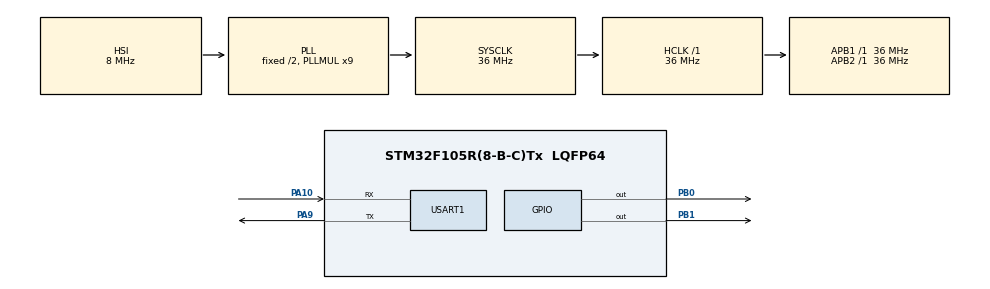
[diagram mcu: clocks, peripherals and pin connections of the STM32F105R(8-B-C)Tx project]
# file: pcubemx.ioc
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FREERTOS.Tasks01=defaultTask,0,128,StartDefaultTask,Default,NULL
Mcu.Family=STM32F1
Mcu.Name=STM32F105R(8-B-C)Tx
Mcu.Package=LQFP64
NVIC.PriorityGroup=NVIC_PRIORITYGROUP_4
NVIC.TIM1_UP_IRQn=true\:0\:0\:false\:false\:true\:false
NVIC.TimeBase=TIM1_UP_IRQn
NVIC.TimeBaseIP=TIM1
NVIC.USART1_IRQn=true\:5\:0\:false\:false\:true\:true
PA10.Mode=Asynchronous
PA10.Signal=USART1_RX
PA13.Mode=Trace_Asynchronous_SW
PA13.Signal=SYS_JTMS-SWDIO
PA14.Mode=Trace_Asynchronous_SW
PA14.Signal=SYS_JTCK-SWCLK
PA9.Mode=Asynchronous
PA9.Signal=USART1_TX
PB0.Signal=GPIO_Output
PB1.Signal=GPIO_Output
PB3.Mode=Trace_Asynchronous_SW
PB3.Signal=SYS_TRACESWO
ProjectManager.HeapSize=0x200
ProjectManager.StackSize=0x400
ProjectManager.TargetToolchain=MDK-ARM V4
RCC.AHBFreq_Value=36000000
RCC.APB1Freq_Value=36000000
RCC.APB1TimFreq_Value=36000000
RCC.APB2Freq_Value=36000000
RCC.APB2TimFreq_Value=36000000
RCC.HCLKFreq_Value=36000000
RCC.PLLMUL=RCC_PLL_MUL9
RCC.SYSCLKFreq_VALUE=36000000
RCC.SYSCLKSource=RCC_SYSCLKSOURCE_PLLCLK
RCC.USBFreq_Value=24000000
USART1.VirtualMode=VM_ASYNC
VP_FREERTOS_VS_ENABLE.Mode=Enabled
VP_SYS_VS_tim1.Mode=TIM1
board=pcubemx

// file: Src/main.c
/**
  ******************************************************************************
  * File Name          : main.c
  * Description        : Main program body
  ******************************************************************************
  * This notice applies to any and all portions of this file
  * that are not between comment pairs USER CODE BEGIN and
  * USER CODE END. Other portions of this file, whether
  * inserted by the user or by software development tools
  * are owned by their respective copyright owners.
  *
  * Copyright (c) 2017 STMicroelectronics International N.V.
  * All rights reserved.
  *
  * Redistribution and use in source and binary forms, with or without
  * modification, are permitted, provided that the following conditions are met:
  *
  * 1. Redistribution of source code must retain the above copyright notice,
  *    this list of conditions and the following disclaimer.
  * 2. Redistributions in binary form must reproduce the above copyright notice,
  *    this list of conditions and the following disclaimer in the documentation
  *    and/or other materials provided with the distribution.
  * 3. Neither the name of STMicroelectronics nor the names of other
  *    contributors to this software may be used to endorse or promote products
  *    derived from this software without specific written permission.
  * 4. This software, including modifications and/or derivative works of this
  *    software, must execute solely and exclusively on microcontroller or
  *    microprocessor devices manufactured by or for STMicroelectronics.
  * 5. Redistribution and use of this software other than as permitted under
  *    this license is void and will automatically terminate your rights under
  *    this license.
  *
  * THIS SOFTWARE IS PROVIDED BY STMICROELECTRONICS AND CONTRIBUTORS "AS IS"
  * AND ANY EXPRESS, IMPLIED OR STATUTORY WARRANTIES, INCLUDING, BUT NOT
  * LIMITED TO, THE IMPLIED WARRANTIES OF MERCHANTABILITY, FITNESS FOR A
  * PARTICULAR PURPOSE AND NON-INFRINGEMENT OF THIRD PARTY INTELLECTUAL PROPERTY
  * RIGHTS ARE DISCLAIMED TO THE FULLEST EXTENT PERMITTED BY LAW. IN NO EVENT
  * SHALL STMICROELECTRONICS OR CONTRIBUTORS BE LIABLE FOR ANY DIRECT, INDIRECT,
  * INCIDENTAL, SPECIAL, EXEMPLARY, OR CONSEQUENTIAL DAMAGES (INCLUDING, BUT NOT
  * LIMITED TO, PROCUREMENT OF SUBSTITUTE GOODS OR SERVICES; LOSS OF USE, DATA,
  * OR PROFITS; OR BUSINESS INTERRUPTION) HOWEVER CAUSED AND ON ANY THEORY OF
  * LIABILITY, WHETHER IN CONTRACT, STRICT LIABILITY, OR TORT (INCLUDING
  * NEGLIGENCE OR OTHERWISE) ARISING IN ANY WAY OUT OF THE USE OF THIS SOFTWARE,
  * EVEN IF ADVISED OF THE POSSIBILITY OF SUCH DAMAGE.
  *
  ******************************************************************************
  */
#include "main.h"
#include "stm32f1xx_hal.h"
#include "cmsis_os.h"

UART_HandleTypeDef huart1;

osThreadId defaultTaskHandle;

/* USER CODE BEGIN PV */
/* Private variables ---------------------------------------------------------*/

/* USER CODE END PV */

void SystemClock_Config(void);
static void MX_GPIO_Init(void);
static void MX_USART1_UART_Init(void);
void StartDefaultTask(void const * argument);

/* USER CODE BEGIN PFP */
/* Private function prototypes -----------------------------------------------*/
void StartDefaultTaskLed(void const * argument);

/* USER CODE END PFP */

int main(void)
{

  /* MCU Configuration----------------------------------------------------------*/

  /* Reset of all peripherals, Initializes the Flash interface and the Systick. */
  HAL_Init();

  /* Configure the system clock */
  SystemClock_Config();

  /* Initialize all configured peripherals */
  MX_GPIO_Init();
  MX_USART1_UART_Init();

  /* Create the thread(s) */
  /* definition and creation of defaultTask */
  osThreadDef(defaultTask, StartDefaultTask, osPriorityNormal, 0, 128);
  defaultTaskHandle = osThreadCreate(osThread(defaultTask), NULL);

  /* USER CODE BEGIN RTOS_THREADS */
  /* add threads, ... */
  osThreadDef(defaultTaskLed, StartDefaultTaskLed, osPriorityNormal, 0, 128);
  osThreadCreate(osThread(defaultTaskLed), NULL);
  /* USER CODE END RTOS_THREADS */

  /* Start scheduler */
  osKernelStart();

  /* We should never get here as control is now taken by the scheduler */

  /* Infinite loop */
  while (1)
  {

  }

}

/** System Clock Configuration
*/
void SystemClock_Config(void)
{

  RCC_OscInitTypeDef RCC_OscInitStruct;
  RCC_ClkInitTypeDef RCC_ClkInitStruct;

    /**Initializes the CPU, AHB and APB busses clocks
    */
  RCC_OscInitStruct.OscillatorType = RCC_OSCILLATORTYPE_HSI;
  RCC_OscInitStruct.HSIState = RCC_HSI_ON;
  RCC_OscInitStruct.HSICalibrationValue = 16;
  RCC_OscInitStruct.Prediv1Source = RCC_PREDIV1_SOURCE_HSE;
  RCC_OscInitStruct.PLL.PLLState = RCC_PLL_ON;
  RCC_OscInitStruct.PLL.PLLSource = RCC_PLLSOURCE_HSI_DIV2;
  RCC_OscInitStruct.PLL.PLLMUL = RCC_PLL_MUL9;
  RCC_OscInitStruct.PLL2.PLL2State = RCC_PLL_NONE;
  if (HAL_RCC_OscConfig(&RCC_OscInitStruct) != HAL_OK)
  {
    _Error_Handler(__FILE__, __LINE__);
  }

    /**Initializes the CPU, AHB and APB busses clocks
    */
  RCC_ClkInitStruct.ClockType = RCC_CLOCKTYPE_HCLK|RCC_CLOCKTYPE_SYSCLK
                              |RCC_CLOCKTYPE_PCLK1|RCC_CLOCKTYPE_PCLK2;
  RCC_ClkInitStruct.SYSCLKSource = RCC_SYSCLKSOURCE_PLLCLK;
  RCC_ClkInitStruct.AHBCLKDivider = RCC_SYSCLK_DIV1;
  RCC_ClkInitStruct.APB1CLKDivider = RCC_HCLK_DIV1;
  RCC_ClkInitStruct.APB2CLKDivider = RCC_HCLK_DIV1;

  if (HAL_RCC_ClockConfig(&RCC_ClkInitStruct, FLASH_LATENCY_1) != HAL_OK)
  {
    _Error_Handler(__FILE__, __LINE__);
  }

    /**Configure the Systick interrupt time
    */
  HAL_SYSTICK_Config(HAL_RCC_GetHCLKFreq()/1000);

    /**Configure the Systick
    */
  HAL_SYSTICK_CLKSourceConfig(SYSTICK_CLKSOURCE_HCLK);

    /**Configure the Systick interrupt time
    */
  __HAL_RCC_PLLI2S_ENABLE();

  /* SysTick_IRQn interrupt configuration */
  HAL_NVIC_SetPriority(SysTick_IRQn, 15, 0);
}

/* USART1 init function */
static void MX_USART1_UART_Init(void)
{

  huart1.Instance = USART1;
  huart1.Init.BaudRate = 115200;
  huart1.Init.WordLength = UART_WORDLENGTH_8B;
  huart1.Init.StopBits = UART_STOPBITS_1;
  huart1.Init.Parity = UART_PARITY_NONE;
  huart1.Init.Mode = UART_MODE_TX_RX;
  huart1.Init.HwFlowCtl = UART_HWCONTROL_NONE;
  huart1.Init.OverSampling = UART_OVERSAMPLING_16;
  if (HAL_UART_Init(&huart1) != HAL_OK)
  {
    _Error_Handler(__FILE__, __LINE__);
  }

}

/** Configure pins as
        * Analog
        * Input
        * Output
        * EVENT_OUT
        * EXTI
*/
static void MX_GPIO_Init(void)
{

  GPIO_InitTypeDef GPIO_InitStruct;

  /* GPIO Ports Clock Enable */
  __HAL_RCC_GPIOB_CLK_ENABLE();
  __HAL_RCC_GPIOA_CLK_ENABLE();

  /*Configure GPIO pin Output Level */
  HAL_GPIO_WritePin(GPIOB, GPIO_PIN_0|GPIO_PIN_1, GPIO_PIN_RESET);

  /*Configure GPIO pins : PB0 PB1 */
  GPIO_InitStruct.Pin = GPIO_PIN_0|GPIO_PIN_1;
  GPIO_InitStruct.Mode = GPIO_MODE_OUTPUT_PP;
  GPIO_InitStruct.Speed = GPIO_SPEED_FREQ_LOW;
  HAL_GPIO_Init(GPIOB, &GPIO_InitStruct);

}

/* USER CODE BEGIN 4 */
void StartDefaultTaskLed(void const * argument)
{
  uint8_t pu8tx[10];
  for(;;)
  {
	HAL_GPIO_TogglePin(GPIOB,GPIO_PIN_0);      // led.bad
	HAL_GPIO_TogglePin(GPIOB,GPIO_PIN_1);  //led.green
	osDelay(500);//ms

	pu8tx[0] = 0x61;
	pu8tx[1] = 0x0d;
	pu8tx[2] = 0x0a;
	HAL_UART_Transmit(&huart1,pu8tx,3,1000);

  }
}

/* USER CODE END 4 */

/* StartDefaultTask function */
void StartDefaultTask(void const * argument)
{

  for(;;)
  {
    osDelay(1);
  }
}

void HAL_TIM_PeriodElapsedCallback(TIM_HandleTypeDef *htim)
{
  if (htim->Instance == TIM1) {
    HAL_IncTick();
  }
}

void _Error_Handler(char * file, int line)
{
  while(1)
  {
  }
}

/************************ (C) COPYRIGHT STMicroelectronics *****END OF FILE****/
